AUTOSAR XML (schema 00046)
package /ComponentTypes
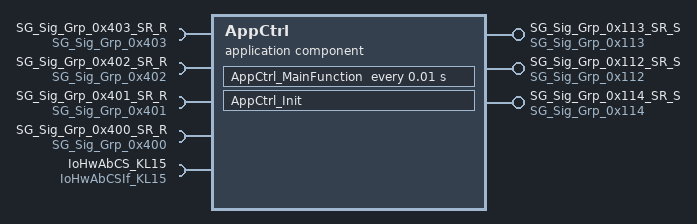
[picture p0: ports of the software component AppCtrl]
  application sw component type AppCtrl
    4 x require port:
      SG_Sig_Grp_0x403_SR_R: nonqueued-receiver-com-spec{data-element=SG_Sig_Grp_0x403, init-value=fields=[Sig_0x403_Used_1:0, Sig_0x403_Used_2:0, Sig_0x403_Used_3:0, Sig_0x403_Used_4:0, Sig_0x403_Used_5:0]}, required-interface=SG_Sig_Grp_0x403
      SG_Sig_Grp_0x402_SR_R: nonqueued-receiver-com-spec{data-element=SG_Sig_Grp_0x402, init-value=fields=[Sig_0x402_Used_1:0, Sig_0x402_Used_2:0, Sig_0x402_Used_3:0, Sig_0x402_Used_4:0, Sig_0x402_Used_5:0]}, required-interface=SG_Sig_Grp_0x402
      SG_Sig_Grp_0x401_SR_R: nonqueued-receiver-com-spec{data-element=SG_Sig_Grp_0x401, init-value=fields=[Button1_Control:0, Button2_Control:0, Button3_Control:0, Button4_Control:0]}, required-interface=SG_Sig_Grp_0x401
      SG_Sig_Grp_0x400_SR_R: nonqueued-receiver-com-spec{data-element=SG_Sig_Grp_0x400, end-to-end-transformation-com-spec-props=disable-end-to-end-check=false, init-value=fields=[CrcSig_Pack_0:0, CrcSig_Pack_1:0, CrcSig_Pack_2:0, Led1_Control:1, Led2_Control:1, Led3_Control:1, Led4_Control:1, SupB_Checksum_0x400:0, SupB_Counter_0x400:0]}, required-interface=SG_Sig_Grp_0x400
    provide port SG_Sig_Grp_0x113_SR_S: nonqueued-sender-com-spec{data-element=SG_Sig_Grp_0x113, init-value=fields=System_Run_Time:20}, provided-interface=SG_Sig_Grp_0x113
    provide port SG_Sig_Grp_0x112_SR_S: nonqueued-sender-com-spec{data-element=SG_Sig_Grp_0x112, init-value=fields=[PowerMode:0, SupA_Checksum_0x112:0, SupA_Counter_0x112:0]}, provided-interface=SG_Sig_Grp_0x112
    require port IoHwAbCS_KL15: client-com-spec=IoHwAbOp_KL15_Read, required-interface=IoHwAbCSIf_KL15
    provide port SG_Sig_Grp_0x114_SR_S: nonqueued-sender-com-spec{data-element=SG_Sig_Grp_0x114, init-value=fields=[Sig_0x114_Used_1:0, Sig_0x114_Used_2:0, Sig_0x114_Used_3:0, Sig_0x114_Used_4:0, Sig_0x114_Used_5:0, Sig_0x114_Used_6:0]}, provided-interface=SG_Sig_Grp_0x114
    behavior AppCtrl_InternalBehavior
      timing event TMT_AppCtrl_MainFunction: start-on-event=AppCtrl_MainFunction, period=0.01
      init event AppCtrl_InitEvent: start-on-event=AppCtrl_Init
      runnable AppCtrl_MainFunction
        data-receive-point-by-arguments:
          4 x access:
            REC_SG_Sig_Grp_0x{400..403}_SR_R_SG_Sig_Grp_0x{400..403}: accessed-variable=SG_Sig_Grp_0x{400..403}_SR_R.SG_Sig_Grp_0x{400..403}
        data-send-points:
          access SEND_SG_Sig_Grp_0x112_SR_R_SG_Sig_Grp_0x112: accessed-variable=SG_Sig_Grp_0x112_SR_S.SG_Sig_Grp_0x112
          access SEND_SG_Sig_Grp_0x113_SR_R_SG_Sig_Grp_0x113: accessed-variable=SG_Sig_Grp_0x113_SR_S.SG_Sig_Grp_0x113
          access SEND_SG_Sig_Grp_0x114_SR_S_SG_Sig_Grp_0x114: accessed-variable=SG_Sig_Grp_0x114_SR_S.SG_Sig_Grp_0x114
        sync call SC_IoHwAbCS_KL15_IoHwAbOp_KL15_Read: operation=IoHwAbCS_KL15.IoHwAbOp_KL15_Read
      runnable AppCtrl_Init
  swc implementation AppCtrl_Implementation: behavior=AppCtrl_InternalBehavior
